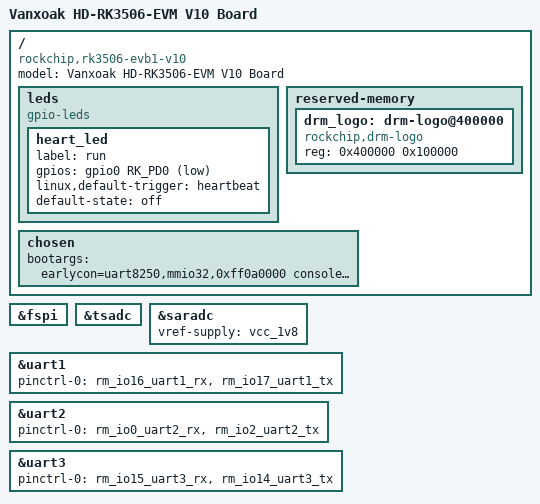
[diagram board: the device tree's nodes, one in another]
// SPDX-License-Identifier: (GPL-2.0+ OR MIT)
/*
 * Copyright (c) 2024 Rockchip Electronics Co., Ltd.
 */

/dts-v1/;

#include "rk3506.dtsi"
#include "vanxoak-hd-rk3506-evb-v1.dtsi"
#include "vanxoak-hd-rk3506-evb-mipi-1024x600.dtsi"
//#include "vanxoak-hd-rk3506-evb-rgb-800x480.dtsi"
//#include "vanxoak-hd-rk3506-evb-rgb-1024x600.dtsi"

/ {
	model = "Vanxoak HD-RK3506-EVM V10 Board";
	compatible = "rockchip,rk3506-evb1-v10", "rockchip,rk3506";
	
  // LED
	leds {
		compatible = "gpio-leds";
		status = "okay";
		heart_led {
			label = "run";
			gpios = <&gpio0 RK_PD0 GPIO_ACTIVE_LOW>;
			linux,default-trigger = "heartbeat";
			default-state = "off";
		};
	};

	reserved-memory {
		#address-cells = <1>;
		#size-cells = <1>;
		ranges;

		drm_logo: drm-logo@400000 {
			compatible = "rockchip,drm-logo";
			reg = <0x400000 0x100000>; 
		};
	};

	chosen {
		bootargs = "earlycon=uart8250,mmio32,0xff0a0000 console=ttyFIQ0 storagemedia=sd root=/dev/mmcblk0p5 rootfstype=ext4 rw rootwait snd_aloop.index=7 snd_aloop.use_raw_jiffies=1";
	};
};

&fspi {
	status = "okay";
};

&tsadc {
	status = "okay";
};

&saradc {
	vref-supply = <&vcc_1v8>;
	status = "okay";
};

&uart1 {
	pinctrl-names = "default";
	pinctrl-0 = <&rm_io16_uart1_rx &rm_io17_uart1_tx>;
	status = "okay";
};

&uart2 {
	pinctrl-names = "default";
	pinctrl-0 = <&rm_io0_uart2_rx &rm_io2_uart2_tx>;
	status = "okay";
};

&uart3 {
	pinctrl-names = "default";
	pinctrl-0 = <&rm_io15_uart3_rx &rm_io14_uart3_tx>;
	status = "okay";
};


